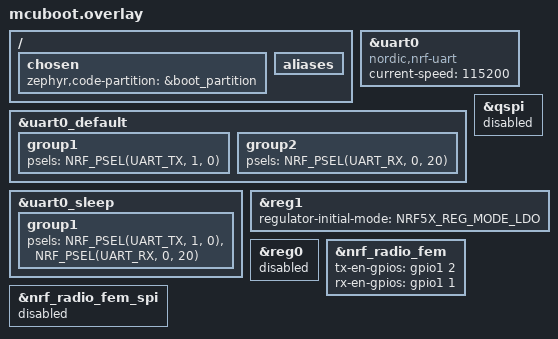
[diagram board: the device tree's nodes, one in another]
/ {
	chosen {
		zephyr,code-partition = &boot_partition;
	};
};

&uart0 {
	compatible = "nordic,nrf-uart";
	current-speed = <115200>;
	status = "okay";
};

&uart0_default {
	group1 {
		psels = <NRF_PSEL(UART_TX, 1, 0)>;
		// psels = <NRF_PSEL(UART_TX, 1, 3)>, <NRF_PSEL(UART_RTS, 1, 4)>;
	};

	group2 {
		psels = <NRF_PSEL(UART_RX, 0, 20)>;
		// psels = <NRF_PSEL(UART_RX, 1, 5)>, <NRF_PSEL(UART_CTS, 1, 6)>;
	};
};

&uart0_sleep {
	group1 {
		psels = <NRF_PSEL(UART_TX, 1, 0)>, <NRF_PSEL(UART_RX, 0, 20)>;
		// psels = <NRF_PSEL(UART_TX, 1, 3)>, <NRF_PSEL(UART_RTS, 1, 4)>, <NRF_PSEL(UART_RX, 1, 5)>, <NRF_PSEL(UART_CTS, 1, 6)>;
	};
};

&qspi {
	status = "disabled";
};
/delete-node/ &button2;

/ {
	aliases {
		/delete-property/ sw2;
	};
};

&reg1 {
	regulator-initial-mode = <NRF5X_REG_MODE_LDO>;
    // regulator-initial-mode = <NRF5X_REG_MODE_DCDC>;
};
&reg0 {
    status = "disabled";
    // status = "okay";
};
&nrf_radio_fem {
	tx-en-gpios = <&gpio1 2 GPIO_ACTIVE_HIGH>;
	rx-en-gpios = <&gpio1 1 GPIO_ACTIVE_HIGH>;
	/delete-property/ pdn-gpios;
	/delete-property/ spi-if;
	/delete-property/ mode-gpios;
	/delete-property/ ant-sel-gpios;
};

&nrf_radio_fem_spi {
	status = "disabled";
};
